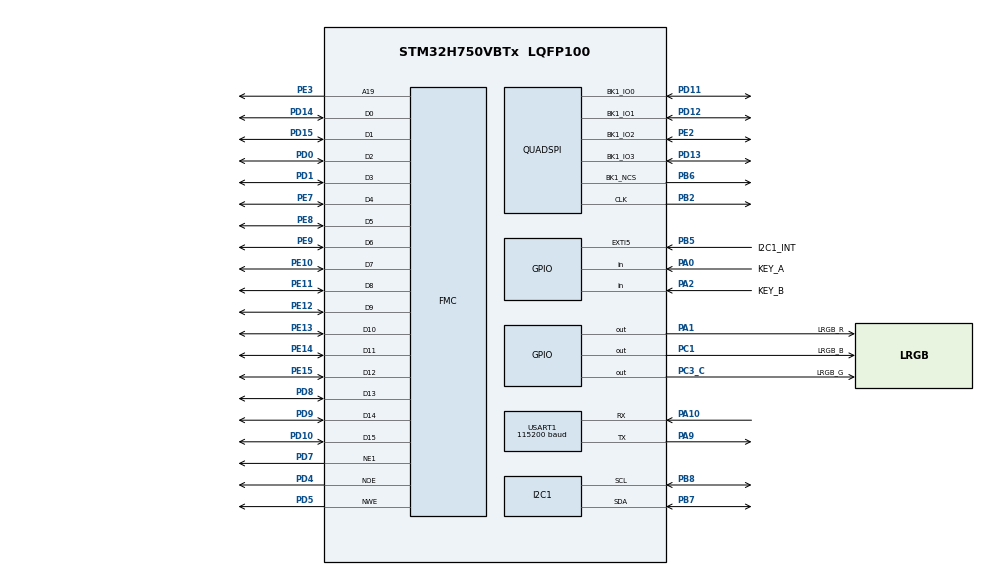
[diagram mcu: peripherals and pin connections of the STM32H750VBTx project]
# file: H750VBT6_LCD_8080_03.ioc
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CORTEX_M7.AccessPermission-Cortex_Memory_Protection_Unit_Region0_Settings=MPU_REGION_FULL_ACCESS
CORTEX_M7.AccessPermission-Cortex_Memory_Protection_Unit_Region1_Settings=MPU_REGION_FULL_ACCESS
CORTEX_M7.AccessPermission-Cortex_Memory_Protection_Unit_Region2_Settings=MPU_REGION_FULL_ACCESS
CORTEX_M7.AccessPermission-Cortex_Memory_Protection_Unit_Region3_Settings=MPU_REGION_FULL_ACCESS
CORTEX_M7.AccessPermission-Cortex_Memory_Protection_Unit_Region4_Settings=MPU_REGION_FULL_ACCESS
CORTEX_M7.AccessPermission-Cortex_Memory_Protection_Unit_Region5_Settings=MPU_REGION_FULL_ACCESS
CORTEX_M7.AccessPermission-Cortex_Memory_Protection_Unit_Region6_Settings=MPU_REGION_FULL_ACCESS
CORTEX_M7.BaseAddress-Cortex_Memory_Protection_Unit_Region0_Settings=0x24000000
CORTEX_M7.BaseAddress-Cortex_Memory_Protection_Unit_Region1_Settings=0x60000000
CORTEX_M7.BaseAddress-Cortex_Memory_Protection_Unit_Region2_Settings=0x30000000
CORTEX_M7.BaseAddress-Cortex_Memory_Protection_Unit_Region3_Settings=0x30020000
CORTEX_M7.BaseAddress-Cortex_Memory_Protection_Unit_Region4_Settings=0x30040000
CORTEX_M7.BaseAddress-Cortex_Memory_Protection_Unit_Region5_Settings=0x38000000
CORTEX_M7.BaseAddress-Cortex_Memory_Protection_Unit_Region6_Settings=0x90000000
CORTEX_M7.CPU_DCache=Enabled
CORTEX_M7.CPU_ICache=Enabled
CORTEX_M7.Enable-Cortex_Memory_Protection_Unit_Region0_Settings=MPU_REGION_ENABLE
CORTEX_M7.Enable-Cortex_Memory_Protection_Unit_Region1_Settings=MPU_REGION_ENABLE
CORTEX_M7.Enable-Cortex_Memory_Protection_Unit_Region2_Settings=MPU_REGION_ENABLE
CORTEX_M7.Enable-Cortex_Memory_Protection_Unit_Region3_Settings=MPU_REGION_ENABLE
CORTEX_M7.Enable-Cortex_Memory_Protection_Unit_Region4_Settings=MPU_REGION_ENABLE
CORTEX_M7.Enable-Cortex_Memory_Protection_Unit_Region5_Settings=MPU_REGION_ENABLE
CORTEX_M7.Enable-Cortex_Memory_Protection_Unit_Region6_Settings=MPU_REGION_ENABLE
CORTEX_M7.IsBufferable-Cortex_Memory_Protection_Unit_Region0_Settings=MPU_ACCESS_BUFFERABLE
CORTEX_M7.IsBufferable-Cortex_Memory_Protection_Unit_Region1_Settings=MPU_ACCESS_BUFFERABLE
CORTEX_M7.IsBufferable-Cortex_Memory_Protection_Unit_Region6_Settings=MPU_ACCESS_BUFFERABLE
CORTEX_M7.IsCacheable-Cortex_Memory_Protection_Unit_Region0_Settings=MPU_ACCESS_CACHEABLE
CORTEX_M7.IsCacheable-Cortex_Memory_Protection_Unit_Region2_Settings=MPU_ACCESS_CACHEABLE
CORTEX_M7.IsCacheable-Cortex_Memory_Protection_Unit_Region3_Settings=MPU_ACCESS_CACHEABLE
CORTEX_M7.IsCacheable-Cortex_Memory_Protection_Unit_Region4_Settings=MPU_ACCESS_CACHEABLE
CORTEX_M7.IsCacheable-Cortex_Memory_Protection_Unit_Region5_Settings=MPU_ACCESS_CACHEABLE
CORTEX_M7.IsCacheable-Cortex_Memory_Protection_Unit_Region6_Settings=MPU_ACCESS_CACHEABLE
CORTEX_M7.MPU_Control=MPU_PRIVILEGED_DEFAULT
CORTEX_M7.Size-Cortex_Memory_Protection_Unit_Region0_Settings=MPU_REGION_SIZE_512KB
CORTEX_M7.Size-Cortex_Memory_Protection_Unit_Region1_Settings=MPU_REGION_SIZE_256MB
CORTEX_M7.Size-Cortex_Memory_Protection_Unit_Region2_Settings=MPU_REGION_SIZE_128KB
CORTEX_M7.Size-Cortex_Memory_Protection_Unit_Region3_Settings=MPU_REGION_SIZE_128KB
CORTEX_M7.Size-Cortex_Memory_Protection_Unit_Region4_Settings=MPU_REGION_SIZE_32KB
CORTEX_M7.Size-Cortex_Memory_Protection_Unit_Region5_Settings=MPU_REGION_SIZE_64KB
CORTEX_M7.Size-Cortex_Memory_Protection_Unit_Region6_Settings=MPU_REGION_SIZE_8MB
CORTEX_M7.TypeExtField-Cortex_Memory_Protection_Unit_Region0_Settings=MPU_TEX_LEVEL1
CORTEX_M7.TypeExtField-Cortex_Memory_Protection_Unit_Region6_Settings=MPU_TEX_LEVEL1
DMA2D.ColorMode=DMA2D_OUTPUT_RGB565
DMA2D.Mode=DMA2D_M2M
FMC.AddressSetupTime1=4
FMC.BusTurnAroundDuration1=6
FMC.DataSetupTime1=15
FMC.ExtendedAddressSetupTime1=4
FMC.ExtendedBusTurnAroundDuration1=6
FMC.ExtendedDataSetupTime1=15
FMC.ExtendedMode1=FMC_EXTENDED_MODE_ENABLE
I2C1.Timing=0x10C0ECFF
Mcu.Family=STM32H7
Mcu.Name=STM32H750VBTx
Mcu.Package=LQFP100
Mcu.UserConstants=QSPI_FLASH_SIZE_2N_OFFSET,0
NVIC.DMA2D_IRQn=true\:1\:0\:true\:false\:true\:true\:true
NVIC.EXTI9_5_IRQn=true\:10\:0\:true\:false\:true\:true\:true
NVIC.PriorityGroup=NVIC_PRIORITYGROUP_4
NVIC.TIM3_IRQn=true\:14\:0\:true\:false\:true\:true\:true
NVIC.TIM6_DAC_IRQn=true\:13\:0\:true\:false\:true\:true\:true
NVIC.USART1_IRQn=true\:3\:0\:true\:false\:true\:true\:true
PA0.GPIO_Label=KEY_A
PA0.GPIO_PuPd=GPIO_PULLDOWN
PA0.Signal=GPIO_Input
PA1.GPIO_Label=LRGB_R
PA1.GPIO_Speed=GPIO_SPEED_FREQ_VERY_HIGH
PA1.PinState=GPIO_PIN_SET
PA1.Signal=GPIO_Output
PA10.Mode=Asynchronous
PA10.Signal=USART1_RX
PA13\ (JTMS/SWDIO).Mode=Serial_Wire
PA13\ (JTMS/SWDIO).Signal=DEBUG_JTMS-SWDIO
PA14\ (JTCK/SWCLK).Mode=Serial_Wire
PA14\ (JTCK/SWCLK).Signal=DEBUG_JTCK-SWCLK
PA2.GPIO_Label=KEY_B
PA2.GPIO_PuPd=GPIO_PULLUP
PA2.Signal=GPIO_Input
PA9.Mode=Asynchronous
PA9.Signal=USART1_TX
PB2.Mode=Single Bank 1
PB2.Signal=QUADSPI_CLK
PB5.GPIO_Label=I2C1_INT
PB5.Signal=GPXTI5
PB6.Mode=Single Bank 1
PB6.Signal=QUADSPI_BK1_NCS
PB7.Mode=I2C
PB7.Signal=I2C1_SDA
PB8.Mode=I2C
PB8.Signal=I2C1_SCL
PC1.GPIO_Label=LRGB_B
PC1.GPIO_Speed=GPIO_SPEED_FREQ_VERY_HIGH
PC1.PinState=GPIO_PIN_SET
PC1.Signal=GPIO_Output
PC14-OSC32_IN\ (OSC32_IN).Mode=LSE-External-Oscillator
PC14-OSC32_IN\ (OSC32_IN).Signal=RCC_OSC32_IN
PC15-OSC32_OUT\ (OSC32_OUT).Mode=LSE-External-Oscillator
PC15-OSC32_OUT\ (OSC32_OUT).Signal=RCC_OSC32_OUT
PC3_C.GPIO_Label=LRGB_G
PC3_C.GPIO_Speed=GPIO_SPEED_FREQ_VERY_HIGH
PC3_C.PinState=GPIO_PIN_SET
PC3_C.Signal=GPIO_Output
PD0.Signal=FMC_D2_DA2
PD1.Signal=FMC_D3_DA3
PD10.Signal=FMC_D15_DA15
PD11.Mode=Single Bank 1
PD11.Signal=QUADSPI_BK1_IO0
PD12.Mode=Single Bank 1
PD12.Signal=QUADSPI_BK1_IO1
PD13.Mode=Single Bank 1
PD13.Signal=QUADSPI_BK1_IO3
PD14.Signal=FMC_D0_DA0
PD15.Signal=FMC_D1_DA1
PD4.Signal=FMC_NOE
PD5.Signal=FMC_NWE
PD7.Mode=NorPsramChipSelect1_1
PD7.Signal=FMC_NE1
PD8.Signal=FMC_D13_DA13
PD9.Signal=FMC_D14_DA14
PE10.Signal=FMC_D7_DA7
PE11.Signal=FMC_D8_DA8
PE12.Signal=FMC_D9_DA9
PE13.Signal=FMC_D10_DA10
PE14.Signal=FMC_D11_DA11
PE15.Signal=FMC_D12_DA12
PE2.Mode=Single Bank 1
PE2.Signal=QUADSPI_BK1_IO2
PE3.Signal=FMC_A19
PE7.Signal=FMC_D4_DA4
PE8.Signal=FMC_D5_DA5
PE9.Signal=FMC_D6_DA6
PH0-OSC_IN\ (PH0).Mode=HSE-External-Oscillator
PH0-OSC_IN\ (PH0).Signal=RCC_OSC_IN
PH1-OSC_OUT\ (PH1).Mode=HSE-External-Oscillator
PH1-OSC_OUT\ (PH1).Signal=RCC_OSC_OUT
ProjectManager.HeapSize=0x800
ProjectManager.StackSize=0x1000
ProjectManager.TargetToolchain=STM32CubeIDE
QUADSPI.ChipSelectHighTime=QSPI_CS_HIGH_TIME_2_CYCLE
QUADSPI.ClockPrescaler=1
QUADSPI.FifoThreshold=32
QUADSPI.FlashSize=QSPI_FLASH_SIZE_2N_OFFSET
QUADSPI.SampleShifting=QSPI_SAMPLE_SHIFTING_HALFCYCLE
RCC.ADCCLockSelection=RCC_ADCCLKSOURCE_PLL2
RCC.ADCFreq_Value=129000000
RCC.APB1Freq_Value=100000000
RCC.APB2Freq_Value=100000000
RCC.APB3Freq_Value=100000000
RCC.APB4Freq_Value=100000000
RCC.CECCLockSelection=RCC_CECCLKSOURCE_LSI
RCC.CKPERSourceSelection=RCC_CLKPSOURCE_HSI
RCC.CSI_VALUE=4000000
RCC.CortexFreq_Value=400000000
RCC.Cortex_Div=SYSTICK_CLKSOURCE_HCLK
RCC.Cortex_DivARG=SystemCoreClock/1000
RCC.D1CPRE=RCC_SYSCLK_DIV1
RCC.D1PPRE=RCC_APB3_DIV2
RCC.D2PPRE1=RCC_APB1_DIV2
RCC.D2PPRE2=RCC_APB2_DIV2
RCC.D3PPRE=RCC_APB4_DIV2
RCC.DFSDMCLockSelection=RCC_DFSDM1CLKSOURCE_D2PCLK1
RCC.DIVM1=32
RCC.DIVM2=32
RCC.DIVM3=32
RCC.DIVN1=400
RCC.DIVN2=129
RCC.DIVN3=129
RCC.DIVP1=2
RCC.DIVP3=2
RCC.DIVQ1=2
RCC.DIVQ2=2
RCC.DIVQ3=2
RCC.DIVR1=2
RCC.DIVR2=2
RCC.DIVR3=2
RCC.DSICLockSelection=RCC_DSICLKSOURCE_PHY
RCC.DSIPHY_Div=8
RCC.DSITX_Div=4
RCC.DSI_PHY_VALUE=12288000
RCC.EXTERNAL_CLOCK_VALUE=12288000
RCC.FDCANCLockSelection=RCC_FDCANCLKSOURCE_PLL
RCC.FMCCLockSelection=RCC_FMCCLKSOURCE_D1HCLK
RCC.HCLKFreq_Value=200000000
RCC.HPRE=RCC_HCLK_DIV2
RCC.HSE_VALUE=25000000
RCC.HSIDiv=RCC_PLLSAIDIVR_1
RCC.HSI_VALUE=64000000
RCC.I2C123CLockSelection=RCC_I2C123CLKSOURCE_D2PCLK1
RCC.I2C4CLockSelection=RCC_I2C4CLKSOURCE_D3PCLK1
RCC.LPTIM1CLockSelection=RCC_LPTIM1CLKSOURCE_D2PCLK1
RCC.LPTIM2CLockSelection=RCC_LPTIM2CLKSOURCE_D3PCLK1
RCC.LPTIM345CLockSelection=RCC_LPTIM345CLKSOURCE_D3PCLK1
RCC.LPUART1CLockSelection=RCC_LPUART1CLKSOURCE_D3PCLK1
RCC.PLL1_VCI_Range-AdvancedSettings=RCC_PLL1VCIRANGE_0
RCC.PLL1_VCO_SEL-AdvancedSettings=RCC_PLL1VCOWIDE
RCC.PLLDSIDev=2
RCC.PLLDSIIDF=DSI_PLL_IN_DIV1
RCC.PLLDSIMult=2
RCC.PLLDSINDIV=20
RCC.PLLDSIODF=DSI_PLL_OUT_DIV1
RCC.PLLSourceVirtual=RCC_PLLSOURCE_HSI
RCC.RC48_VALUE=48000000
RCC.RCC_MCO1Source=RCC_MCO1SOURCE_HSI
RCC.RCC_MCO2Source=RCC_MCO2SOURCE_SYSCLK
RCC.RCC_MCODiv1=RCC_MCODIV_1
RCC.RCC_MCODiv2=RCC_MCODIV_1
RCC.RCC_RTC_Clock_Source_FROM_HSE=RCC_RTCCLKSOURCE_HSE_DIV2
RCC.RNGCLockSelection=RCC_RNGCLKSOURCE_HSI48
RCC.SAI1CLockSelection=RCC_SAI1CLKSOURCE_PLL
RCC.SAI23CLockSelection=RCC_SAI23CLKSOURCE_PLL
RCC.SAI4ACLockSelection=RCC_SAI4ACLKSOURCE_PLL
RCC.SAI4BCLockSelection=RCC_SAI4BCLKSOURCE_PLL
RCC.SPDIFCLockSelection=RCC_SPDIFRXCLKSOURCE_PLL
RCC.SPI123CLockSelection=RCC_SPI123CLKSOURCE_PLL
RCC.SPI6CLockSelection=RCC_SPI6CLKSOURCE_D3PCLK1
RCC.SWPCLockSelection=RCC_SWPMI1CLKSOURCE_D2PCLK1
RCC.SYSCLKFreq_VALUE=400000000
RCC.SYSCLKSource=RCC_SYSCLKSOURCE_PLLCLK
RCC.Spi45ClockSelection=RCC_SPI45CLKSOURCE_D2PCLK1
RCC.USART16CLockSelection=RCC_USART16CLKSOURCE_D2PCLK2
RCC.USART234578CLockSelection=RCC_USART234578CLKSOURCE_D2PCLK1
RCC.USBCLockSelection=RCC_USBCLKSOURCE_PLL
RCC.USBFreq_Value=400000000
SH.FMC_A19.0=FMC_A19,A19_1
SH.FMC_D0_DA0.0=FMC_D0,16b-d1
SH.FMC_D10_DA10.0=FMC_D10,16b-d1
SH.FMC_D11_DA11.0=FMC_D11,16b-d1
SH.FMC_D12_DA12.0=FMC_D12,16b-d1
SH.FMC_D13_DA13.0=FMC_D13,16b-d1
SH.FMC_D14_DA14.0=FMC_D14,16b-d1
SH.FMC_D15_DA15.0=FMC_D15,16b-d1
SH.FMC_D1_DA1.0=FMC_D1,16b-d1
SH.FMC_D2_DA2.0=FMC_D2,16b-d1
SH.FMC_D3_DA3.0=FMC_D3,16b-d1
SH.FMC_D4_DA4.0=FMC_D4,16b-d1
SH.FMC_D5_DA5.0=FMC_D5,16b-d1
SH.FMC_D6_DA6.0=FMC_D6,16b-d1
SH.FMC_D7_DA7.0=FMC_D7,16b-d1
SH.FMC_D8_DA8.0=FMC_D8,16b-d1
SH.FMC_D9_DA9.0=FMC_D9,16b-d1
SH.FMC_NOE.0=FMC_NOE,Lcd1
SH.FMC_NWE.0=FMC_NWE,Lcd1
TIM3.AutoReloadPreload=TIM_AUTORELOAD_PRELOAD_ENABLE
TIM3.Channel-Output\ Compare1\ No\ Output=TIM_CHANNEL_1
TIM3.Channel-Output\ Compare2\ No\ Output=TIM_CHANNEL_2
TIM3.Channel-Output\ Compare3\ No\ Output=TIM_CHANNEL_3
TIM3.Channel-Output\ Compare4\ No\ Output=TIM_CHANNEL_4
TIM3.OC1Preload=DISABLE
TIM3.OCMode_1=TIM_OCMODE_TOGGLE
TIM3.OCMode_2=TIM_OCMODE_TIMING
TIM3.OCMode_3=TIM_OCMODE_TIMING
TIM3.OCMode_4=TIM_OCMODE_TIMING
TIM6.AutoReloadPreload=TIM_AUTORELOAD_PRELOAD_ENABLE
TIM6.Period=50000 - 1
TIM6.Prescaler=100 - 1
USART1.BaudRate=115200
USART1.VirtualMode-Asynchronous=VM_ASYNC
VP_DMA2D_VS_DMA2D.Mode=DMA2D_Activate
VP_TIM3_VS_no_output1.Mode=Output Compare1 No Output
VP_TIM3_VS_no_output2.Mode=Output Compare2 No Output
VP_TIM3_VS_no_output3.Mode=Output Compare3 No Output
VP_TIM3_VS_no_output4.Mode=Output Compare4 No Output
VP_TIM6_VS_ClockSourceINT.Mode=Enable_Timer
board=custom

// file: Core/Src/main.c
/* USER CODE BEGIN Header */
/**
  ******************************************************************************
  * @file           : main.c
  * @brief          : Main program body
  ******************************************************************************
  * @attention
  *
  * <h2><center>&copy; Copyright (c) 2022 STMicroelectronics.
  * All rights reserved.</center></h2>
  *
  * This software component is licensed by ST under BSD 3-Clause license,
  * the "License"; You may not use this file except in compliance with the
  * License. You may obtain a copy of the License at:
  *                        opensource.org/licenses/BSD-3-Clause
  *
  ******************************************************************************
  */
/* USER CODE END Header */
#include "main.h"
#include "dma2d.h"
#include "i2c.h"
#include "tim.h"
#include "usart.h"
#include "gpio.h"
#include "fmc.h"

/* USER CODE BEGIN Includes */
#include "cppports.h"
/* USER CODE END Includes */

void SystemClock_Config(void);
static void MPU_Config(void);

int main(void)
{
  /* USER CODE BEGIN 1 */
	SCB->VTOR = 0x90000000; /* 设置中断向量表地�? */
  /* USER CODE END 1 */

  /* MPU Configuration--------------------------------------------------------*/
  MPU_Config();

  /* Enable I-Cache---------------------------------------------------------*/
  SCB_EnableICache();

  /* Enable D-Cache---------------------------------------------------------*/
  SCB_EnableDCache();

  /* MCU Configuration--------------------------------------------------------*/

  /* Reset of all peripherals, Initializes the Flash interface and the Systick. */
  HAL_Init();

  /* Configure the system clock */
  SystemClock_Config();

  /* Initialize all configured peripherals */
  MX_GPIO_Init();
  MX_USART1_UART_Init();
  MX_TIM6_Init();
  MX_TIM3_Init();
  MX_FMC_Init();
  MX_DMA2D_Init();
  MX_I2C1_Init();
  /* USER CODE BEGIN 2 */
  setup();
  loop();
  /* USER CODE END 2 */

  /* Infinite loop */
  while (1)
  {

  }
}

void SystemClock_Config(void)
{
  RCC_OscInitTypeDef RCC_OscInitStruct = {0};
  RCC_ClkInitTypeDef RCC_ClkInitStruct = {0};

  /** Supply configuration update enable
  */
  HAL_PWREx_ConfigSupply(PWR_LDO_SUPPLY);
  /** Configure the main internal regulator output voltage
  */
  __HAL_PWR_VOLTAGESCALING_CONFIG(PWR_REGULATOR_VOLTAGE_SCALE1);

  while(!__HAL_PWR_GET_FLAG(PWR_FLAG_VOSRDY)) {}
  /** Initializes the RCC Oscillators according to the specified parameters
  * in the RCC_OscInitTypeDef structure.
  */
  RCC_OscInitStruct.OscillatorType = RCC_OSCILLATORTYPE_HSI;
  RCC_OscInitStruct.HSIState = RCC_HSI_DIV1;
  RCC_OscInitStruct.HSICalibrationValue = RCC_HSICALIBRATION_DEFAULT;
  RCC_OscInitStruct.PLL.PLLState = RCC_PLL_ON;
  RCC_OscInitStruct.PLL.PLLSource = RCC_PLLSOURCE_HSI;
  RCC_OscInitStruct.PLL.PLLM = 32;
  RCC_OscInitStruct.PLL.PLLN = 400;
  RCC_OscInitStruct.PLL.PLLP = 2;
  RCC_OscInitStruct.PLL.PLLQ = 2;
  RCC_OscInitStruct.PLL.PLLR = 2;
  RCC_OscInitStruct.PLL.PLLRGE = RCC_PLL1VCIRANGE_1;
  RCC_OscInitStruct.PLL.PLLVCOSEL = RCC_PLL1VCOWIDE;
  RCC_OscInitStruct.PLL.PLLFRACN = 0;
  if (HAL_RCC_OscConfig(&RCC_OscInitStruct) != HAL_OK)
  {
    Error_Handler();
  }
  /** Initializes the CPU, AHB and APB buses clocks
  */
  RCC_ClkInitStruct.ClockType = RCC_CLOCKTYPE_HCLK|RCC_CLOCKTYPE_SYSCLK
                              |RCC_CLOCKTYPE_PCLK1|RCC_CLOCKTYPE_PCLK2
                              |RCC_CLOCKTYPE_D3PCLK1|RCC_CLOCKTYPE_D1PCLK1;
  RCC_ClkInitStruct.SYSCLKSource = RCC_SYSCLKSOURCE_PLLCLK;
  RCC_ClkInitStruct.SYSCLKDivider = RCC_SYSCLK_DIV1;
  RCC_ClkInitStruct.AHBCLKDivider = RCC_HCLK_DIV2;
  RCC_ClkInitStruct.APB3CLKDivider = RCC_APB3_DIV2;
  RCC_ClkInitStruct.APB1CLKDivider = RCC_APB1_DIV2;
  RCC_ClkInitStruct.APB2CLKDivider = RCC_APB2_DIV2;
  RCC_ClkInitStruct.APB4CLKDivider = RCC_APB4_DIV2;

  if (HAL_RCC_ClockConfig(&RCC_ClkInitStruct, FLASH_LATENCY_2) != HAL_OK)
  {
    Error_Handler();
  }
}

/* MPU Configuration */

void MPU_Config(void)
{
  MPU_Region_InitTypeDef MPU_InitStruct = {0};

  /* Disables the MPU */
  HAL_MPU_Disable();
  /** Initializes and configures the Region and the memory to be protected
  */
  MPU_InitStruct.Enable = MPU_REGION_ENABLE;
  MPU_InitStruct.Number = MPU_REGION_NUMBER0;
  MPU_InitStruct.BaseAddress = 0x24000000;
  MPU_InitStruct.Size = MPU_REGION_SIZE_512KB;
  MPU_InitStruct.SubRegionDisable = 0x0;
  MPU_InitStruct.TypeExtField = MPU_TEX_LEVEL1;
  MPU_InitStruct.AccessPermission = MPU_REGION_FULL_ACCESS;
  MPU_InitStruct.DisableExec = MPU_INSTRUCTION_ACCESS_ENABLE;
  MPU_InitStruct.IsShareable = MPU_ACCESS_NOT_SHAREABLE;
  MPU_InitStruct.IsCacheable = MPU_ACCESS_CACHEABLE;
  MPU_InitStruct.IsBufferable = MPU_ACCESS_BUFFERABLE;

  HAL_MPU_ConfigRegion(&MPU_InitStruct);
  /** Initializes and configures the Region and the memory to be protected
  */
  MPU_InitStruct.Number = MPU_REGION_NUMBER1;
  MPU_InitStruct.BaseAddress = 0x60000000;
  MPU_InitStruct.Size = MPU_REGION_SIZE_256MB;
  MPU_InitStruct.TypeExtField = MPU_TEX_LEVEL0;
  MPU_InitStruct.IsCacheable = MPU_ACCESS_NOT_CACHEABLE;

  HAL_MPU_ConfigRegion(&MPU_InitStruct);
  /** Initializes and configures the Region and the memory to be protected
  */
  MPU_InitStruct.Number = MPU_REGION_NUMBER2;
  MPU_InitStruct.BaseAddress = 0x30000000;
  MPU_InitStruct.Size = MPU_REGION_SIZE_128KB;
  MPU_InitStruct.IsCacheable = MPU_ACCESS_CACHEABLE;
  MPU_InitStruct.IsBufferable = MPU_ACCESS_NOT_BUFFERABLE;

  HAL_MPU_ConfigRegion(&MPU_InitStruct);
  /** Initializes and configures the Region and the memory to be protected
  */
  MPU_InitStruct.Number = MPU_REGION_NUMBER3;
  MPU_InitStruct.BaseAddress = 0x30020000;

  HAL_MPU_ConfigRegion(&MPU_InitStruct);
  /** Initializes and configures the Region and the memory to be protected
  */
  MPU_InitStruct.Number = MPU_REGION_NUMBER4;
  MPU_InitStruct.BaseAddress = 0x30040000;
  MPU_InitStruct.Size = MPU_REGION_SIZE_32KB;

  HAL_MPU_ConfigRegion(&MPU_InitStruct);
  /** Initializes and configures the Region and the memory to be protected
  */
  MPU_InitStruct.Number = MPU_REGION_NUMBER5;
  MPU_InitStruct.BaseAddress = 0x38000000;
  MPU_InitStruct.Size = MPU_REGION_SIZE_64KB;

  HAL_MPU_ConfigRegion(&MPU_InitStruct);
  /** Initializes and configures the Region and the memory to be protected
  */
  MPU_InitStruct.Number = MPU_REGION_NUMBER6;
  MPU_InitStruct.BaseAddress = 0x90000000;
  MPU_InitStruct.Size = MPU_REGION_SIZE_8MB;
  MPU_InitStruct.TypeExtField = MPU_TEX_LEVEL1;
  MPU_InitStruct.IsBufferable = MPU_ACCESS_BUFFERABLE;

  HAL_MPU_ConfigRegion(&MPU_InitStruct);
  /* Enables the MPU */
  HAL_MPU_Enable(MPU_PRIVILEGED_DEFAULT);

}

void Error_Handler(void)
{
  __disable_irq();
  while (1)
  {
  }
}

/************************ (C) COPYRIGHT STMicroelectronics *****END OF FILE****/
